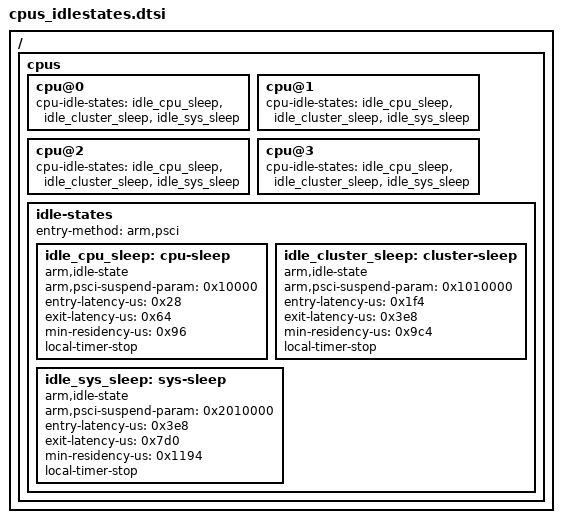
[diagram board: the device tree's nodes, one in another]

/* experimentally */

/ {
	cpus {
		cpu@0 {
			cpu-idle-states = <&idle_cpu_sleep &idle_cluster_sleep &idle_sys_sleep>;
		};

		cpu@1 {
			cpu-idle-states = <&idle_cpu_sleep &idle_cluster_sleep &idle_sys_sleep>;
		};

		cpu@2 {
			cpu-idle-states = <&idle_cpu_sleep &idle_cluster_sleep &idle_sys_sleep>;
		};

		cpu@3 {
			cpu-idle-states = <&idle_cpu_sleep &idle_cluster_sleep &idle_sys_sleep>;
		};


		idle-states {
			entry-method = "arm,psci";

			idle_cpu_sleep: cpu-sleep {
				compatible = "arm,idle-state";

				arm,psci-suspend-param = <0x10000>;
				entry-latency-us = <0x28>;
				exit-latency-us = <0x64>;
				min-residency-us = <0x96>;

				local-timer-stop;
			};

			idle_cluster_sleep: cluster-sleep {
				compatible = "arm,idle-state";

				arm,psci-suspend-param = <0x1010000>;
				entry-latency-us = <0x1f4>;
				exit-latency-us = <0x3e8>;
				min-residency-us = <0x9c4>;

				local-timer-stop;
			};

			idle_sys_sleep: sys-sleep {
				compatible = "arm,idle-state";

				arm,psci-suspend-param = <0x2010000>;
				entry-latency-us = <0x3e8>;
				exit-latency-us = <0x7d0>;
				min-residency-us = <0x1194>;

				local-timer-stop;
			};
		};
	};

	/*psci {
		compatible = "arm,psci-0.2";
		method = "smc";

		psci_version = <0x84000000>;
		cpu_suspend = <0xc4000001>;
		cpu_off = <0x84000002>;
		cpu_on = <0xc4000003>;
		affinity_info = <0xc4000004>;
		migrate = <0xc4000005>;
		migrate_info_type = <0x84000006>;
		migrate_info_up_cpu = <0xc4000007>;
		system_off = <0x84000008>;
		system_reset = <0x84000009>;
	};*/
};


